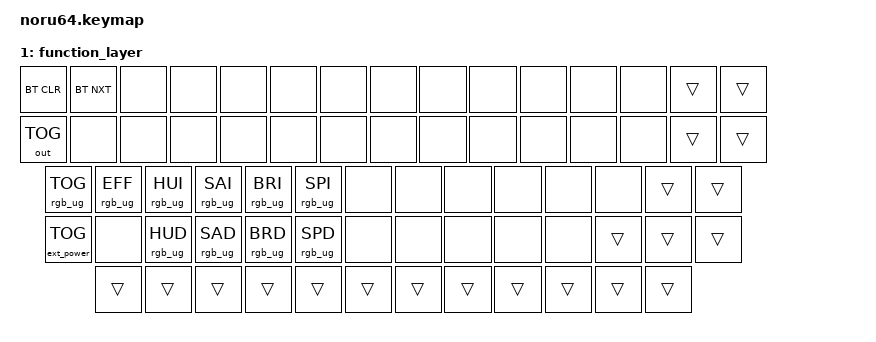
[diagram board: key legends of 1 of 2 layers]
/*
# Copyright (c) 2021 The ZMK Contributors
*
* SPDX-License-Identifier: MIT
*/

#include <behaviors.dtsi>
#include <dt-bindings/zmk/keys.h>
#include <dt-bindings/zmk/rgb.h>
#include <dt-bindings/zmk/bt.h>
#include <dt-bindings/zmk/outputs.h>
#include <dt-bindings/zmk/ext_power.h>

/ {
	keymap {
		compatible = "zmk,keymap";
		default_layer {
			bindings = <
        &kp GRAVE &kp N1  &kp N2  &kp N3 &kp N4  &kp N5  &kp N6            &kp N7  &kp N8   &kp N9   &kp N0   &kp MINUS &kp EQUAL      &kp BSPC      &kp HOME
		&kp TAB   &kp Q   &kp W   &kp E     &kp R  &kp T                   &kp Y    &kp U   &kp I    &kp O    &kp P     &kp LBKT  &kp RBKT  &kp BSLH &kp END
		&kp CAPS &kp A    &kp S    &kp D     &kp F  &kp G                  &kp H      &kp J     &kp K     &kp L     &kp SEMI  &kp SQT       &kp RET  &kp PG_UP 
		&kp LSHFT &kp Z    &kp X    &kp C     &kp V  &kp B                 &kp N      &kp M     &kp COMMA  &kp DOT    &kp FSLH   &kp RSHFT  &kp UP   &kp PG_DN
		&kp LCTRL &kp LGUI &kp LALT       &kp SPACE    &mo 1                    &kp SPACE                &kp RALT   &kp RCTRL      &kp LEFT &kp DOWN &kp RIGHT
			>;
		};
		function_layer {
			bindings = <
        &bt BT_CLR       &bt BT_NXT            &none            &none            &none   &none            &none        &none   &none   &none   &none   &none   &none  &trans      &trans
  		&out OUT_TOG            &none            &none            &none            &none                    &none        &none   &none   &none   &none   &none   &none   &none  &trans  &trans
  		&rgb_ug RGB_TOG  &rgb_ug RGB_EFF  &rgb_ug RGB_HUI  &rgb_ug RGB_SAI  &rgb_ug RGB_BRI          &rgb_ug RGB_SPI        &none           &none   &none   &none   &none   &none  &trans  &trans
  		&ext_power EP_TOG            &none  &rgb_ug RGB_HUD  &rgb_ug RGB_SAD  &rgb_ug RGB_BRD          &rgb_ug RGB_SPD        &none           &none   &none   &none   &none  &trans  &trans  &trans
  		&trans           &trans           &trans           &trans             &trans                              &trans                  &trans  &trans  &trans  &trans  &trans  &trans
			>;
		};
	};
};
